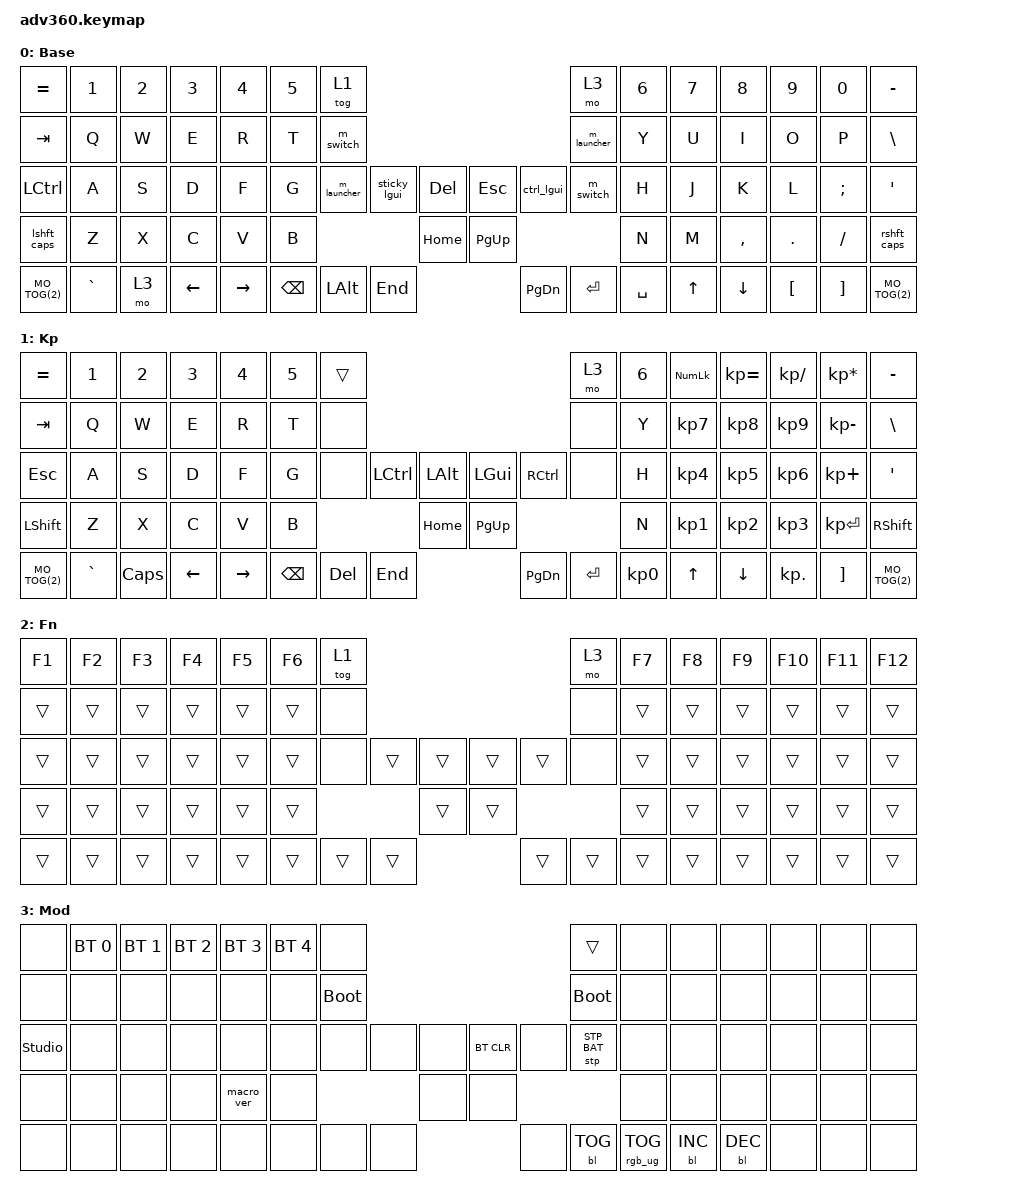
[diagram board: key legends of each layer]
#include <behaviors.dtsi>
#include <dt-bindings/zmk/keys.h>
#include <dt-bindings/zmk/bt.h>
#include <dt-bindings/zmk/rgb.h>
#include <dt-bindings/zmk/stp.h>
#include <dt-bindings/zmk/backlight.h>
#include <dt-bindings/zmk/pointing.h>

// https://zmk.dev/docs/keymaps/behaviors/hold-tap?examples=mo_tog
#define MO_TOG(layer) &mo_tog layer layer

/ {
    behaviors {
      #include "macros.dtsi"
      #include "version.dtsi"

      hm: homerow_mods {
          compatible = "zmk,behavior-hold-tap";
          label = "HOMEROW_MODS";
          #binding-cells = <2>;
          tapping-term-ms = <200>;
          quick_tap_ms = <175>;
          flavor = "tap-preferred";
          bindings = <&kp>, <&kp>;
      };

      lshft_caps: double_tap_lshift_caps {
                  compatible = "zmk,behavior-tap-dance";
                  label = "double_tap_lshift_caps";
                  #binding-cells = <0>;
                  bindings = <&kp LSHFT>, <&kp CAPS>;
      };

      rshft_caps: double_tap_rshift_caps {
                  compatible = "zmk,behavior-tap-dance";
                  label = "double_tap_rshift_caps";
                  #binding-cells = <0>;
                  bindings = <&kp RSHFT>, <&kp CAPS>;
      };

      m_launcher: macro_launcher {
                  compatible = "zmk,behavior-macro";
                  label = "macro_launcher";
                  #binding-cells = <0>;
                  bindings = <&kp LG(SPACE)>;
      };

      m_switch: macro_switch {
                compatible = "zmk,behavior-macro";
                label = "macro_switch";
                #binding-cells = <0>;
                bindings = <&kp LG(TAB)>;
      };

      sticky_lgui: double_tap_lgui_sticky {
                   compatible = "zmk,behavior-tap-dance";
                   label = "double_tap_lgui_sticky";
                   #binding-cells = <0>;
                   bindings = <&kp LGUI>, <&sk LGUI>;
      };

      ctrl_lgui: double_tap_ctrl_lgui_sticky {
      		 compatible = "zmk,behavior-tap-dance";
		 label = "double_tap_ctrl_lgui_sticky";
		 #binding-cells = <0>;
		 bindings = <&kp RCTRL>, <&sk LGUI>;
      };

      mo_tog: behavior_mo_tog {
            compatible = "zmk,behavior-hold-tap";
            #binding-cells = <2>;
            flavor = "hold-preferred";
            tapping-term-ms = <200>;
            bindings = <&mo>, <&tog>;
      };
    };

  keymap {
    compatible = "zmk,keymap";

    default_layer {
      display-name = "Base";
      bindings = <
        &kp EQUAL   &kp N1    &kp N2   &kp N3   &kp N4     &kp N5 &tog 1                                                               &mo 3       &kp N6 &kp N7 &kp N8    &kp N9   &kp N0   &kp MINUS
        &kp TAB     &kp Q     &kp W    &kp E    &kp R      &kp T  &m_switch                                                            &m_launcher &kp Y  &kp U  &kp I     &kp O    &kp P    &kp BSLH
        &kp LCTRL   &kp A     &kp S    &kp D    &kp F      &kp G  &m_launcher     &sticky_lgui  &kp DEL  &kp ESC   &ctrl_lgui          &m_switch   &kp H  &kp J  &kp K     &kp L    &kp SEMI &kp SQT
        &lshft_caps &kp Z     &kp X    &kp C    &kp V      &kp B                                &kp HOME &kp PG_UP                                 &kp N  &kp M  &kp COMMA &kp DOT  &kp FSLH &rshft_caps
        MO_TOG(2)   &kp GRAVE &mo 3    &kp LEFT &kp RIGHT                &kp BSPC &kp LALT      &kp END  &kp PG_DN &kp ENTER &kp SPACE                    &kp UP &kp DOWN  &kp LBKT &kp RBKT MO_TOG(2)
      >;
    };
    keypad {
      display-name = "Kp";
      bindings = <
        &kp EQUAL &kp N1    &kp N2   &kp N3   &kp N4     &kp N5 &trans                                                           &mo 3 &kp N6 &kp KP_NUM &kp KP_EQUAL &kp KP_DIVIDE &kp KP_MULTIPLY &kp MINUS
        &kp TAB   &kp Q     &kp W    &kp E    &kp R      &kp T  &none                                                            &none &kp Y  &kp KP_N7  &kp KP_N8    &kp KP_N9     &kp KP_MINUS    &kp BSLH
        &kp ESC   &kp A     &kp S    &kp D    &kp F      &kp G  &none           &kp LCTRL &kp LALT &kp LGUI  &kp RCTRL           &none &kp H  &kp KP_N4  &kp KP_N5    &kp KP_N6     &kp KP_PLUS     &kp SQT
        &kp LSHFT &kp Z     &kp X    &kp C    &kp V      &kp B                            &kp HOME &kp PG_UP                           &kp N  &kp KP_N1  &kp KP_N2    &kp KP_N3     &kp KP_ENTER    &kp RSHFT
        MO_TOG(2) &kp GRAVE &kp CAPS &kp LEFT &kp RIGHT                &kp BSPC &kp DEL   &kp END  &kp PG_DN &kp ENTER &kp KP_N0              &kp UP     &kp DOWN     &kp KP_DOT    &kp RBKT        MO_TOG(2)
      >;
    };
    fn {
      display-name = "Fn";
      bindings = <
        &kp F1 &kp F2 &kp F3 &kp F4 &kp F5 &kp F6 &tog 1                                           &mo 3 &kp F7 &kp F8 &kp F9 &kp F10 &kp F11 &kp F12
        &trans &trans &trans &trans &trans &trans  &none                                           &none &trans &trans &trans &trans  &trans  &trans
        &trans &trans &trans &trans &trans &trans  &none        &trans &trans &trans &trans        &none &trans &trans &trans &trans  &trans  &trans
        &trans &trans &trans &trans &trans &trans                      &trans &trans                     &trans &trans &trans &trans  &trans  &trans
        &trans &trans &trans &trans &trans               &trans &trans &trans &trans &trans &trans              &trans &trans &trans  &trans  &trans
      >;
    };
    mod {
      display-name = "Mod";
      bindings = <
        &none &bt BT_SEL 0 &bt BT_SEL 1 &bt BT_SEL 2 &bt BT_SEL 3 &bt BT_SEL 4 &none                                                                     &trans                 &none        &none        &none        &none &none &none
        &none &none        &none        &none        &none        &none        &bootloader                                                               &bootloader            &none        &none        &none        &none &none &none
        &studio_unlock &none        &none        &none        &none        &none        &none                   &none &none &bt BT_CLR &none                      &stp STP_BAT &none        &none        &none        &none &none &none
        &none &none        &none        &none        &macro_ver   &none                                      &none &none                                                        &none        &none        &none        &none &none &none
        &none &none        &none        &none        &none                                       &none &none &none &none      &bl BL_TOG &rgb_ug RGB_TOG                                     &bl BL_INC   &bl BL_DEC   &none &none &none
      >;
    };
    extra1 {
      display-name = "Red";
      status = "reserved";
    };

    extra2 {
      display-name = "Purple";
      status = "reserved";
    };

    extra3 {
      display-name = "Cyan";
      status = "reserved";
    };

    extra4 {
      display-name = "Yellow";
      status = "reserved";
    };
  };
};
